# RAMCTL_367.0_config2 register map
Vendor: Texas Instruments
Peripheral module from a debugger description file (folder msp430).
Registers are 16-bit, read-write, no defined reset value unless marked. A register's access mark holds for its fields unless they carry their own. Offsets are as the file gives them; lines under a group give offsets from that group; [hi:lo] are bit positions; {n}, {i} and the like mark numbered series; 'fields as' and 'values as' point back to an identical list; <NAME> marks a mode.

## RAMCTL
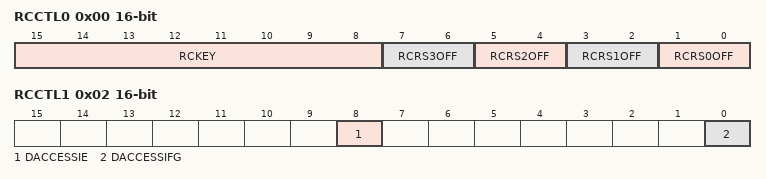
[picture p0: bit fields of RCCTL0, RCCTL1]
0x00 RCCTL0 — RAM Controller Control 0
  [15:8] RCKEY — RAM controller key. Always reads as 69h. Must be written as 5Ah; any other write is is ignored.
  [7:6] RCRS3OFF — RAM controller RAM sector 3 off
    0=RCRS0OFF_0 (Contents of this RAM sector are retained in LPM3 and LPM4.); 1=RCRS0OFF_1 (Turns off this RAM sector in LPM3 and LPM4, re-activates it on wake-up. All data of this RAM sector is lost after wakeup from LPM3 and LPM4. See the device-specific data sheet to find the number of available sectors, the address range, and the size of each RAM sector.); 2=RCRS0OFF_2 (Turns off this RAM sector entering LPM3 and LPM4, the RAM sector remains off after wake-up. All data of this RAM sector is lost. See the devicespecific data sheet to find the number of available sectors, the address range, and the size of each RAM sector.)
  [5:4] RCRS2OFF — RAM controller RAM sector 2 off
    values as RCRS3OFF
  [3:2] RCRS1OFF — RAM controller RAM sector 1 off
    values as RCRS3OFF
  [1:0] RCRS0OFF — RAM controller RAM sector 0 off
    0=Contents of this RAM sector are retained in LPM3 and LPM4; 1=Turns off this RAM sector in LPM3 and LPM4, re-activates it on wake-up. All data of this RAM sector is lost after wakeup from LPM3 and LPM4. See the device-specific data sheet to find the number of available sectors, the address range, and the size of each RAM sector.; 2=Turns off this RAM sector entering LPM3 and LPM4, the RAM sector remains off after wake-up. All data of this RAM sector is lost. See the devicespecific data sheet to find the number of available sectors, the address range, and the size of each RAM sector.
0x02 RCCTL1 — RAM Controller Control 1
  [8] DACCESSIE — DACCESS Bus Error NMI enable
    0=Disable NMI for DACCESS Interrupt; 1=Enable NMI for DACCESS Interrupt
  [0] DACCESSIFG — DACCESS Interrupt Flag
    0=DACCESS Interrupt is not pending; 1=DACCESS Interrupt is pending
